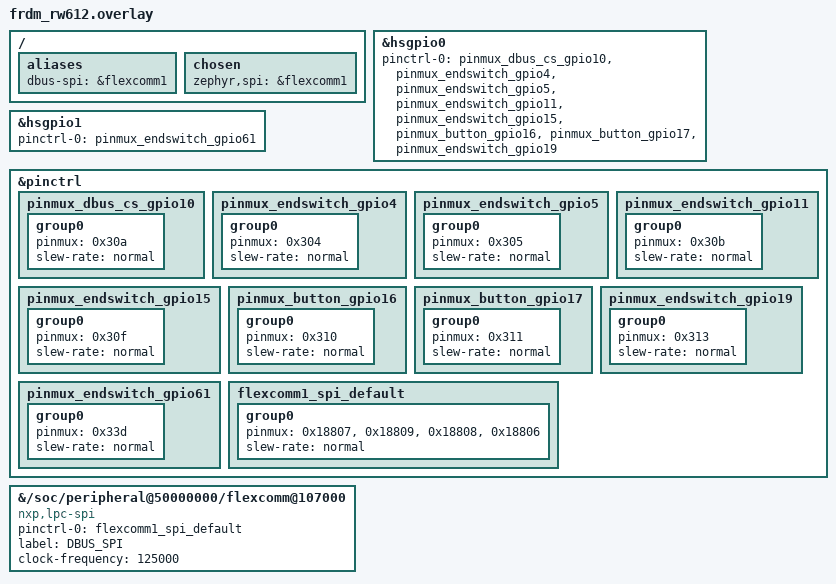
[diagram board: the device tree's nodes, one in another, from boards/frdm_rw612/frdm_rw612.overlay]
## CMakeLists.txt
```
cmake_minimum_required(VERSION 3.20.0)

if(NOT DEFINED DTC_OVERLAY_FILE OR DTC_OVERLAY_FILE STREQUAL "")
	set(_dbus_overlay "${CMAKE_CURRENT_SOURCE_DIR}/boards/frdm_rw612/frdm_rw612.overlay")
	if(EXISTS "${_dbus_overlay}")
		set(DTC_OVERLAY_FILE "${_dbus_overlay}" CACHE STRING "Default devicetree overlay" FORCE)
	endif()
endif()

find_package(Zephyr REQUIRED HINTS $ENV{ZEPHYR_BASE})
project(zephyr_dbus_driver)

# Add your source files here
target_sources(app PRIVATE src/main.c src/dbus_app_layer.c src/spi_abstraction.c src/dbus_config.c src/dbus_driver.c src/StdCrc.c src/motor_service.c src/lcd_service.c src/ultrasonic_service.c)
target_include_directories(app PRIVATE inc src)
target_compile_definitions(app PRIVATE ARCH_STACK_PTR_ALIGN=8) # Define for main application build
```

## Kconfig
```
config PRINTK_WAITTIME_MS
    int "Waittime in ms"
    default 100
    help
      Defines the waittime in ms after which
      "Hello World!" is printed to the console

source "Kconfig.zephyr"

config DBAL_CROSS_CONNECTION
	bool "Enable DBAL Cross Connection"
	default n
	help
		Enable this option to allow cross-connection functionality in the DBus Application Layer.

config DBAL_TARGET_ADDRESS
	hex "DBAL Target Address"
	default 0x00
	help
		Defines the target address for the DBus Application Layer.
		This address is used to identify the communication partner.

config DBAL_TX_THREAD_STACK_SIZE
	int "DBAL Transmit Thread Stack Size"
	default 4096
	help
		Stack size for the DBus Application Layer Transmit thread.

config DBAL_RX_THREAD_STACK_SIZE
	int "DBAL Receive Thread Stack Size"
	default 4096
	help
		Stack size for the DBus Application Layer Receive thread.
```

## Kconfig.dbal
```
menu "DBus Application Layer Configuration"

config DBAL_CROSS_CONNECTION
    bool "Enable DBAL Cross Connection"
    default y
    help
        Enable support for DBAL cross-connection features.

config DBAL_TX_THREAD_STACK_SIZE
    int "DBAL Transmit Thread Stack Size"
    default 4096
    depends on DBAL_CROSS_CONNECTION
    help
        Stack size for the DBus Application Layer Transmit Thread.

config DBAL_RX_THREAD_STACK_SIZE
    int "DBAL Receive Thread Stack Size"
    default 4096
    depends on DBAL_CROSS_CONNECTION
    help
        Stack size for the DBus Application Layer Receive Thread.

config DBAL_TARGET_ADDRESS
    hex "DBAL Target Address"
    default 0x01
    help
        The target address for DBAL communication.

endmenu
```

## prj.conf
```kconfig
# ==============================
# 🔧 Zephyr Kernel Configuration
# ==============================
CONFIG_MAIN_STACK_SIZE=4096
CONFIG_ISR_STACK_SIZE=2048
CONFIG_SYSTEM_WORKQUEUE_STACK_SIZE=2048
CONFIG_LOG_PROCESS_THREAD_STACK_SIZE=2048
CONFIG_HEAP_MEM_POOL_SIZE=1024
CONFIG_SYS_CLOCK_EXISTS=y
CONFIG_SYS_CLOCK_TICKS_PER_SEC=1000

# Thread diagnostics and safety
CONFIG_THREAD_NAME=y
CONFIG_THREAD_STACK_INFO=y
CONFIG_STACK_SENTINEL=y
CONFIG_STACK_CANARIES=y
CONFIG_THREAD_ANALYZER=y
CONFIG_THREAD_ANALYZER_AUTO=n
CONFIG_THREAD_ANALYZER_RUN_UNLOCKED=y
CONFIG_THREAD_ANALYZER_USE_PRINTK=y

# ==============================
# 🧾 Logging / Console
# ==============================
CONFIG_PRINTK=y
CONFIG_CONSOLE=y
CONFIG_SERIAL=y
CONFIG_UART_CONSOLE=y
CONFIG_LOG=y
CONFIG_LOG_DEFAULT_LEVEL=3
CONFIG_LOG_MODE_DEFERRED=y
CONFIG_LOG_PROCESS_THREAD=y
CONFIG_LOG_PROCESS_THREAD_STACK_SIZE=2048
CONFIG_LOG_BACKEND_UART=y
CONFIG_LOG_BUFFER_SIZE=2048

# RTT console for debugging (optional but great for NXP boards)
CONFIG_USE_SEGGER_RTT=y
CONFIG_LOG_BACKEND_RTT=y
CONFIG_SEGGER_RTT_BUFFER_SIZE_UP=4096
CONFIG_SEGGER_RTT_PRINTF_BUFFER_SIZE=512
CONFIG_RTT_CONSOLE=y

# ==============================
# ⚙️ Drivers
# ==============================
CONFIG_GPIO=y
CONFIG_SPI=y
CONFIG_SPI_ASYNC=y
CONFIG_SPI_INIT_PRIORITY=70
CONFIG_SPI_MCUX_FLEXCOMM=y

# ==============================
# 💾 Floating-Point Unit (optional)
# ==============================
# Only enable if your app really needs FPU math
# Otherwise it bloats context switching and stack usage
# Disable if not using floats in your code
CONFIG_FPU=y
CONFIG_FPU_SHARING=y

# ==============================
# 🧩 Custom DBAL (DBus Application Layer)
# ==============================
CONFIG_DBAL_CROSS_CONNECTION=y
CONFIG_DBAL_TARGET_ADDRESS=0x00
CONFIG_DBAL_TX_THREAD_STACK_SIZE=4096
CONFIG_DBAL_RX_THREAD_STACK_SIZE=4096

# ==============================
# 🧪 Testing (optional)
# ==============================
# CONFIG_ZTEST=y

# ==============================
# 🧠 Misc sanity
# ==============================
CONFIG_STACK_ALIGN_DOUBLE_WORD=y
CONFIG_KERNEL_INIT_PRIORITY_DEFAULT=90
```

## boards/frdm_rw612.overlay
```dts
/* frdm_rw612.overlay
 * SPI-Master setup for FRDM-RW612 using Flexcomm1
 */

#include <nxp/rw/RW612-pinctrl.h>

/ {
    aliases {
        dbus-spi = &flexcomm1;  /* alias for convenience */
    };

    chosen {
        zephyr,spi = &flexcomm1;
    };
};

&hsgpio0 {
    status = "okay";
};

/* Define pin configuration for SPI (manual CS via GPIO6). */
&pinctrl {
    flexcomm1_spi_default: flexcomm1_spi_default {
        group0 {
            pinmux = <0x18807>,  /* SCK  -> GPIO7 */
                     <0x18809>,  /* MOSI -> GPIO9 */
                     <0x18808>;  /* MISO -> GPIO8 */
            slew-rate = "normal";
        };
    };
};

/* Override SPI controller node. */
&flexcomm1 {
    status = "okay";
    compatible = "nxp,lpc-spi";
    pinctrl-0 = <&flexcomm1_spi_default>;
    pinctrl-names = "default";
    clock-frequency = <125000>;
};
```

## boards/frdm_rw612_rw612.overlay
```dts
/* Qualifier-specific overlay for frdm_rw612/rw612 */

#include "frdm_rw612.overlay"
```

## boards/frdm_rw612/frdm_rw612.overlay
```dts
/* frdm_rw612.overlay
 * SPI-Master setup for FRDM-RW612 using Flexcomm1
 */

#include <nxp/rw/RW612-pinctrl.h>

/ {
    aliases {
        dbus-spi = &flexcomm1;  // alias for convenience
    };

    chosen {
        zephyr,spi = &flexcomm1;
    };
};

&hsgpio0 {
    status = "okay";
    pinctrl-0 = <&pinmux_dbus_cs_gpio10
                 &pinmux_endswitch_gpio4
                 &pinmux_endswitch_gpio5
                 &pinmux_endswitch_gpio11
                 &pinmux_endswitch_gpio15
                 &pinmux_button_gpio16
                 &pinmux_button_gpio17
                 &pinmux_endswitch_gpio19>;
    pinctrl-names = "default";
};

&hsgpio1 {
    status = "okay";
    pinctrl-0 = <&pinmux_endswitch_gpio61>;
    pinctrl-names = "default";
};

/* --- Define pin configuration for SPI --- */
&pinctrl {
    pinmux_dbus_cs_gpio10: pinmux_dbus_cs_gpio10 {
        group0 {
            pinmux = <0x30a>; /* GPIO10 as HSGPIO0_10 for secondary Pico CS */
            slew-rate = "normal";
        };
    };

    pinmux_endswitch_gpio4: pinmux_endswitch_gpio4 {
        group0 {
            pinmux = <0x304>; /* GPIO4 as HSGPIO0_4 for motor1 max/end */
            slew-rate = "normal";
        };
    };

    pinmux_endswitch_gpio5: pinmux_endswitch_gpio5 {
        group0 {
            pinmux = <0x305>; /* GPIO5 as HSGPIO0_5 for motor2 min/home */
            slew-rate = "normal";
        };
    };

    pinmux_endswitch_gpio11: pinmux_endswitch_gpio11 {
        group0 {
            pinmux = <0x30b>; /* GPIO11 as HSGPIO0_11 for motor2 max/end */
            slew-rate = "normal";
        };
    };

    pinmux_endswitch_gpio15: pinmux_endswitch_gpio15 {
        group0 {
            pinmux = <0x30f>; /* GPIO15 as HSGPIO0_15 for motor1 min/home */
            slew-rate = "normal";
        };
    };

    pinmux_button_gpio16: pinmux_button_gpio16 {
        group0 {
            pinmux = <0x310>; /* GPIO16 as HSGPIO0_16 for alternate trigger button */
            slew-rate = "normal";
        };
    };

    pinmux_button_gpio17: pinmux_button_gpio17 {
        group0 {
            pinmux = <0x311>; /* GPIO17 as HSGPIO0_17 for combined-test trigger button */
            slew-rate = "normal";
        };
    };

    pinmux_endswitch_gpio19: pinmux_endswitch_gpio19 {
        group0 {
            pinmux = <0x313>; /* GPIO19 as HSGPIO0_19 for motor0 end-switch max/end */
            slew-rate = "normal";
        };
    };

    pinmux_endswitch_gpio61: pinmux_endswitch_gpio61 {
        group0 {
            pinmux = <0x33d>; /* GPIO61 as HSGPIO1_29 for motor0 end-switch min/home */
            slew-rate = "normal";
        };
    };

    flexcomm1_spi_default: flexcomm1_spi_default {
        group0 {
            pinmux = <0x18807>,  /* SCK  -> GPIO7   */
                     <0x18809>,  /* MOSI -> GPIO9   */
                     <0x18808>,  /* MISO -> GPIO8   */
                     <0x18806>;  /* SSEL0 -> GPIO6  */
            slew-rate = "normal";
        };
    };
};

/* --- Forcefully override SPI controller node --- */
&{/soc/peripheral@50000000/flexcomm@107000} {
    status = "okay";
    compatible = "nxp,lpc-spi";
    pinctrl-0 = <&flexcomm1_spi_default>;
    pinctrl-names = "default";
    label = "DBUS_SPI";
    /* CS is handled manually via HSGPIO GPIO6/GPIO10 in dbus_driver.c. */
    clock-frequency = <125000>; /* Set to 125kHz as per working BSHG example */
};
```

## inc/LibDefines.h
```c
#ifndef LIB_DEFINES_H
#define LIB_DEFINES_H

// Placeholder for common library definitions
// Add any necessary definitions here to allow compilation

// Example of a macro that might be in LibDefines.h
#define LD_STRINGIZE_NX(x) #x
#define LD_STRINGIZE(x) LD_STRINGIZE_NX(x)

#endif // LIB_DEFINES_H
```

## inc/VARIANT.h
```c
#ifndef VARIANT_H
#define VARIANT_H

// Placeholder for variant-specific definitions
// Add any necessary definitions here to allow compilation
// For example, if a specific macro is expected:
// #define SOME_VARIANT_SPECIFIC_MACRO_VALUE 1

#endif // VARIANT_H
```

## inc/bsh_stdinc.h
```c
#ifndef BSH_STDINC_H
#define BSH_STDINC_H

#ifdef __cplusplus
extern "C" {
#endif

#include "LibDefines.h"
#include LD_STRINGIZE(VARIANT.h) // include the header for current variant

// Placeholder for other standard includes or definitions from original bsh_stdinc.h
// For example, if it defines common integer types:
// #include <stdint.h>
// #include <stdbool.h>

#ifdef __cplusplus
}
#endif

#endif // BSH_STDINC_H
```

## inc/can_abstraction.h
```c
#ifndef ZEPHYR_CAN_ABSTRACTION_H__
#define ZEPHYR_CAN_ABSTRACTION_H__

#include <zephyr/kernel.h>
#include <stdbool.h>
#include <stdint.h>

/**
 * @brief Initializes the CAN abstraction layer.
 *
 * This function initializes the underlying Zephyr CAN device.
 *
 * @return True if initialization is successful, false otherwise.
 */
bool can_abstraction_init(void);

/**
 * @brief Sends a CAN message.
 *
 * @param id The CAN message ID.
 * @param data Pointer to the data to send.
 * @param len Length of the data.
 *
 * @return True if the message is successfully queued for transmission, false otherwise.
 */
bool can_abstraction_send(uint32_t id, const uint8_t *data, uint8_t len);

/**
 * @brief Registers a callback for CAN message reception.
 *
 * @param callback The function to call when a CAN message is received.
 */
void can_abstraction_register_rx_callback(void (*callback)(uint32_t id, const uint8_t *data, uint8_t len));

#endif // ZEPHYR_CAN_ABSTRACTION_H__
```

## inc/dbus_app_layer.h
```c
#ifndef ZEPHYR_DBUS_APP_LAYER_H__
#define ZEPHYR_DBUS_APP_LAYER_H__

#include <zephyr/kernel.h>
#include <stdbool.h>
#include <stdint.h>

// Define a structure for SPI received messages to be put into a message queue
#define DBAL_SPI_RX_MSG_MAX_SIZE    128 // Max size of an SPI message payload
#define DBAL_SPI_RX_MSG_QUEUE_DEPTH 10  // Depth of the message queue

struct dbal_spi_rx_msg {
    uint8_t data[DBAL_SPI_RX_MSG_MAX_SIZE];
    uint8_t len;
};

// Define uchar for compatibility with original code
typedef unsigned char uchar;

// Forward declaration for internal instance structure, if needed
// Define some constants from the original DBAL for Zephyr porting
#define DBAL_MAX_MSGS2REPEAT        10U // Example value, adjust as needed
#define DBAL_DBUS_RETRY_MAX         3U  // Example value, adjust as needed
#define DBAL_RESPONSE_TIME_MS       100 // Example value, adjust as needed
#define DBAL_DBUS_RECOVERY_TIME_MS  500 // Example value, adjust as needed

// Define message index constants (from original bustypes.h or similar)
#define DBAL_MSG_INDEX_APP_LAYER_CONNECTION 0U
#define DBAL_MSG_INDEX_APP_LAYER_REQUEST    1U
#define DBAL_MSG_INDEX_APP_LAYER_RESPONSE   2U
#define DBAL_MSG_INDEX_CROSS_OFFSET         3U // Offset for cross-connection messages
#define DBAL_MSG_INDEX_APP_LAYER_CROSS_CON  (DBAL_MSG_INDEX_APP_LAYER_CONNECTION + DBAL_MSG_INDEX_CROSS_OFFSET)
#define DBAL_MSG_INDEX_APP_LAYER_CROSS_REQ  (DBAL_MSG_INDEX_APP_LAYER_REQUEST + DBAL_MSG_INDEX_CROSS_OFFSET)
#define DBAL_MSG_INDEX_APP_LAYER_CROSS_RESP (DBAL_MSG_INDEX_APP_LAYER_RESPONSE + DBAL_MSG_INDEX_CROSS_OFFSET)
#define DBAL_MSG_INDEX_COUNT                6U // Total number of message indices

// Define offsets within the DBus frame (from original BshDBus2AppLayer.c comments)
#define DBAL_MSG_SENDER                     0U
#define DBAL_MSG_PROTOCOL_TYPE              1U
#define DBAL_MSG_SEQID                      2U
#define DBAL_CON_MSG_TYPE                   2U
#define DBAL_CON_MSG_PROTOCOL_VERSION       3U
#define DBAL_CON_MSG_LEN                    4U // Length of connection message

#define DBAL_FRAME_PAYLOADLEN               1U
#define DBAL_FRAME_SERVICE_ID_HI            2U
#define DBAL_FRAME_SERVICE_ID_LO            3U
#define DBAL_FRAME_COMMAND_ID_HI            4U
#define DBAL_FRAME_COMMAND_ID_LO            5U
#define DBAL_FRAME_DATA_OFFSET              6U // Offset to actual data in a DBAL frame

#define BYTE_SIZE                           8U // For bit shifting

// Placeholder for DBAL_LAST_MSG2REPEAT (from original BshDBus2AppLayer.c)
#define DBAL_LAST_MSG2REPEAT                (DBAL_MAX_MSGS2REPEAT - 1U)

// Placeholder for DBAL_BUFFER_SIZE (from original BshDBus2AppLayer.c)
#define DBAL_BUFFER_SIZE                    128U // Example buffer size, adjust as needed

// SPI Message Framing
#define SPI_SOF_BYTE                        0xAA // Start of Frame byte
#define SPI_LENGTH_OFFSET                   1U   // Offset for length byte after SOF
#define SPI_CRC_OFFSET                      2U   // Offset for CRC byte after SOF and Length
#define SPI_HEADER_LEN                      3U   // SOF + Length + CRC byte

// CRC-8 definitions (example, adjust polynomial and initial value as needed)
#define CRC8_POLYNOMIAL                     0x07 // CRC-8-SAE J1850 polynomial
#define CRC8_INITIAL_VALUE                  0xFF

// Placeholder for DLL_ACK_STATUS values (from original dbusdll.h or similar)
#define DLL_ACK_NOT_RECEIVED                0U
#define DLL_ACK_OK                          1U
// Add other DLL_ACK_STATUS values as needed (e.g., DLL_ACK_BUSY, DLL_ACK_WRONG, DLL_ACK_TRANSMISSION_ABORTED)

// Placeholder for DBAL_ConnectionSmEvent (from original BshDBus2AppLayer_internal.h or similar)
enum DBAL_ConnectionSmEvent {
    DBAL_CON_SM_EVENT_ENABLE_REQUEST,
    DBAL_CON_SM_EVENT_ACCEPT,
    DBAL_CON_SM_EVENT_DISABLE_REQUEST,
    DBAL_CON_SM_EVENT_DISABLE_RESPONSE, // Added
    DBAL_CON_SM_EVENT_DISABLE_SILENT,
    DBAL_CON_SM_EVENT_REJECT,
    DBAL_CON_SM_EVENT_TEMP_ENABLE_REQUEST,
    DBAL_CON_SM_EVENT_TEMP_DISABLE_REQUEST
};

// Placeholder for DBAL_Dbus2FrameType (from original BshDBus2AppLayer_internal.h or similar)
enum DBAL_Dbus2FrameType {
    DBAL_DBUS2_FRAME_TYPE_REQ,
    DBAL_DBUS2_FRAME_TYPE_RESP,
    DBAL_DBUS2_FRAME_TYPE_CON,
    DBAL_DBUS2_FRAME_TYPE_UNKNOWN
};

// Placeholder for DBAL_Msgs2RepeatStatus (from original BshDBus2AppLayer_internal.h or similar)
enum DBAL_Msgs2RepeatStatus {
    DBAL_MSG2REPEAT_NONE,
    DBAL_MSG2REPEAT_EXIST
};

// Placeholder for DBAL_CODE_SEC_TASK and other code section masks
#define DBAL_CODE_SEC_TASK                  0x01U
#define DBAL_CODE_SEC_REQ_RESP_POST         0x02U
#define DBAL_CODE_SEC_CR_REQ_RESP_POST      0x04U
#define DBAL_CODE_SEC_REP_TIMER             0x08U

// Placeholder for DBAL_ConnectionState (from original IoConnectionHandling.h or similar)
enum DBAL_ConnectionState {
    DBAL_CONNECTIONSTATE_DISCONNECTED,
    DBAL_CONNECTIONSTATE_CONNECTING,
    DBAL_CONNECTIONSTATE_CONNECTED,
    DBAL_CONNECTIONSTATE_DISCONNECTING
};

// Placeholder for DBALCR_ParticipantType (from original BshDBus2AppLayerCross.h)
enum DBALCR_ParticipantType
{
    DBALCR_PART_TYPE_NONE,
    DBALCR_PART_TYPE_CLIENT,
    DBALCR_PART_TYPE_SERVER
};

// Forward declaration for internal instance structure
struct dbal_instance;

// Prototype for timer callbacks (Zephyr k_timer_handler_t signature)
void dbal_con_msg_timer_cb(struct k_timer *timer_id);
void dbal_msg_timer_cb(struct k_timer *timer_id);

/** \enum   DBAL_CommState
 *
 * \brief   Value that represents the current communication status.
 *
 * \details For meaning of values see general DBal specification.
**/
enum DBAL_CommState
{
    DBAL_COMMSTATE_DISCONNECTED = 0, // Initial state
    DBAL_COMMSTATE_NOT_READY,        // Renamed from 0 to 1
    DBAL_COMMSTATE_CONNECTING,       // Added
    DBAL_COMMSTATE_CONNECTED,
    DBAL_COMMSTATE_DISCONNECTING     // Added
};

/** \enum   DBAL_MessageType
 *
 * \brief   Value that represents the DBal specific message type for communication.
 *
 * \details For meaning of values see general DBal specification.
**/
enum DBAL_MessageType
{
    DBAL_TYPE_CMD,
    DBAL_TYPE_CMD_ACK,
    DBAL_TYPE_QUERY,
    DBAL_TYPE_QUERY_ACK,
    DBAL_TYPE_EVENT,
    DBAL_TYPE_EVENT_ACK,
    DBAL_TYPE_UNKNOWN
};

/** \enum   DBAL_ConnectionMessageType
 *
 * \brief   Value that represents the action in the connection handling.
 *
 * \details For meaning of values see general DBal specification.
**/
enum DBAL_ConnectionMessageType
{
    DBAL_CON_ENABLE_REQUEST = 0,
    DBAL_CON_ENABLE_RESPONSE,
    DBAL_CON_DISABLE_REQUEST,
    DBAL_CON_DISABLE_RESPONSE,
    DBAL_CON_PING_REQUEST,
    DBAL_CON_PING_RESPONSE,
    DBAL_CON_TEMP_ENABLE_REQUEST,
    DBAL_CON_TEMP_ENABLE_RESPONSE,
    DBAL_CON_TEMP_DISABLE_REQUEST,
    DBAL_CON_TEMP_DISABLE_RESPONSE,
    DBAL_CON_MSG_TYPE_COUNT
};

typedef void (*DBAL_ioCommStateCb)(enum DBAL_CommState CommState);
typedef void (*DBAL_ioMsgLostCb)(uint16_t ServiceId, uint16_t CommandId, const uint8_t* const Bytes, uint8_t DataLen);

/** \struct DBAL_Identifier
 *
 * \brief   Structure for the identification of a DBal message with a given ServiceId.
 *
 * \details For meaning of parameters see general DBal specification.
**/
struct DBAL_Identifier
{
    uint16_t                        CommandId;
    enum DBAL_MessageType           Type;
};

typedef void (*DBAL_Service)(const uint8_t* const Data, uint8_t DataLen);

/** \struct DBAL_ReceiveObject
 *
 * \brief   Structure for handling an incoming dbal message.
**/
struct DBAL_ReceiveObject
{
    struct DBAL_Identifier      Identifier;
    DBAL_Service                Service;
};

#ifdef CONFIG_DBAL_CROSS_CONNECTION
/** \struct DBALCR_ObjectTableEntry
 *
 * \brief   Structure for handling an incoming dbal cross-connection message.
 **/
struct DBALCR_ObjectTableEntry
{
    const void*                 ReceiveObject;
    uint16_t                    ServiceId;
    uint8_t                     ReceiveObjectSize;
};
#endif // CONFIG_DBAL_CROSS_CONNECTION

// Structure to hold registered service handlers
#define DBAL_MAX_SERVICE_HANDLERS 5 // Example max number of service handlers
struct DBAL_ServiceHandler {
    uint16_t ServiceId;
    enum DBAL_MessageType Type;
    DBAL_Service Handler;
};

// Public function declarations
void dbal_init(void);
bool dbal_send_cmd_response(uint16_t service_id, uint16_t command_id, const uint8_t* data, uint8_t data_len);
bool dbal_send_query_response(uint16_t service_id, uint16_t command_id, const uint8_t* data, uint8_t data_len);
bool dbal_send_event(uint16_t service_id, uint16_t command_id, const uint8_t* data, uint8_t data_len);

/**
 * @brief Registers a DBus service handler.
 *
 * @param service_id The ID of the service to register.
 * @param type The message type (CMD, QUERY, EVENT) this handler is for.
 * @param handler The callback function to be executed when a matching message is received.
 *
 * @return True if registration is successful, false otherwise.
 */
bool dbal_register_service_handler(uint16_t service_id, enum DBAL_MessageType type, DBAL_Service handler);

/**
 * @brief Gets the current connection state of the DBAL instance.
 *
 * @return The current DBAL_CommState.
 */
enum DBAL_CommState dbal_get_connection_state(void);

// Public function declarations for DBus Lock functionality
bool dbal_apply_dbus_lock(void);
void dbal_release_dbus_lock(void);
bool dbal_is_dbus_lock_active(void);

/**
 * @brief Sends an ACK or NACK message in response to a received message.
 *
 * @param service_id The service ID of the received message.
 * @param command_id The command ID of the received message.
 * @param success True if the received message was processed successfully, false for NACK.
 * @return True if the ACK/NACK message was successfully sent, false otherwise.
 */
bool dbal_send_ack_nack(uint16_t service_id, uint16_t command_id, bool success);

// Test-only functions for service handler management
uint8_t dbal_get_num_service_handlers(void);
void dbal_reset_service_handlers_for_test(void);

#endif // ZEPHYR_DBUS_APP_LAYER_H__
```

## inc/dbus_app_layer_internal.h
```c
#ifndef ZEPHYR_DBUS_APP_LAYER_INTERNAL_H__
#define ZEPHYR_DBUS_APP_LAYER_INTERNAL_H__

#include <zephyr/kernel.h>
#include <stdbool.h>
#include <stdint.h>
#include <zephyr/sys/atomic.h>
#include "dbus_app_layer.h" // Include main header for DBAL_MessageType, DBAL_CommState, DBAL_MAX_MSGS2REPEAT, DBAL_ioMsgLostCb

// Internal structure for a message to be repeated
struct dbal_msg_to_repeat {
    bool IsSlotOccupied;
    uint8_t MsgRetryCounter;
    enum DBAL_MessageType DbalType; // Assuming DBAL_MessageType is defined in dbus_app_layer.h
    uint16_t ServiceId;
    uint16_t CommandId;
    uint8_t Datalen;
    uint8_t Data[64]; // Example max data length, adjust as needed
};

// Internal structure for the DBAL instance
struct dbal_instance {
    uint8_t DBUS_ComPartner;
    uint8_t DBUS_ComBackup;
    uint8_t SendRetryCounter[3]; // Assuming 3 message types for now (connection, request, response)
    struct k_timer ConMsgTimer; // Zephyr timer for connection messages
    struct k_timer MsgTimer;    // Zephyr timer for general messages
    uint8_t ConnectTransmitBuffer[4]; // Example size for connection messages
    uint8_t ConnectDataLen;
    uint8_t TransmitBuffer[128]; // Example max transmit buffer size
    uint8_t TransmitDataLen;
    uint8_t DbalFrames2TransmitCnt;
    uint8_t SeqId2Send;
    uint8_t LastSeqIdReceived;
    bool DisableReqReceived;
    enum DBAL_CommState IoCurrentConnectionState; // Placeholder for connection state
    struct dbal_msg_to_repeat Msgs2Repeat[DBAL_MAX_MSGS2REPEAT]; // Assuming DBAL_MAX_MSGS2REPEAT is defined in dbus_app_layer.h
    struct dbal_msg_to_repeat* MsgRptPtrs[DBAL_MAX_MSGS2REPEAT]; // Pointers for managing the queue
    uint8_t ConRepeatCnt;
    uint8_t LastSendingStatus[3]; // Placeholder for DLL_ACK_STATUS
    DBAL_ioMsgLostCb IoMsgLostCbArray[1]; // Placeholder for message lost callback
    uint8_t IoMsgLostCbCounter;
    uint8_t CodeSectionBitMask; // Placeholder for critical section flags
};

// Global instance for simplicity, or could be managed via a context pointer
extern struct dbal_instance g_dbal_main_instance;

#endif // ZEPHYR_DBUS_APP_LAYER_INTERNAL_H__
```

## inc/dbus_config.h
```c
#ifndef ZEPHYR_DBUS_CONFIG_H__
#define ZEPHYR_DBUS_CONFIG_H__

#include <stdint.h>
#include <stdbool.h>
#include "dbus_app_layer.h" // Include for DBAL_ReceiveObject and DBAL_Identifier

// Define constants from original DBal_cfg.c or derived from it
#define DBAL_OWN_NODE_ADDRESS       0x10U // Example: Own node address
#define DBAL_APPLIANCE_LAYER        0x01U // Example: Appliance layer protocol type
#define DBAL_PROTOCOL_VERSION       0x01U // Example: DBAL protocol version
#define DBAL_PRELIMINARY_PARTNER_ADDR 0x00U // Example: Preliminary partner address

// Placeholder for DBAL_ObjectTable and DBAL_ObjectTableSize
// These would typically be defined by the application using the DBAL
// For now, we'll provide a dummy structure.
struct DBAL_ObjectTableEntry {
    const struct DBAL_ReceiveObject *ReceiveObject;
    const uint16_t                  ServiceId;
    const uint8_t                   ReceiveObjectCount;
};

// Example dummy table and size
extern const struct DBAL_ObjectTableEntry DBAL_ObjectTable[];
extern const uint8_t DBAL_ObjectTableSize;

// Placeholder for cross-connection configurations if CONFIG_DBAL_CROSS_CONNECTION is enabled
#ifdef CONFIG_DBAL_CROSS_CONNECTION
#define DBAL_CROSS_CONNECT_COUNT    1U // Example: Number of cross connections
extern uint8_t DBALCR_ComPartners[DBAL_CROSS_CONNECT_COUNT];
extern enum DBALCR_ParticipantType DBALCR_RolesTowardPartners[DBAL_CROSS_CONNECT_COUNT];
extern uint16_t DBALCR_PingTimeMs;
#endif // CONFIG_DBAL_CROSS_CONNECTION

#endif // ZEPHYR_DBUS_CONFIG_H__
```

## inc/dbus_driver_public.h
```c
#ifndef DBUS_DRIVER_PUBLIC_H__
#define DBUS_DRIVER_PUBLIC_H__

#include "dbus_driver_config.h" // For MCAL_Error, DBC_Error, DBC_Cfg_t, etc.
#include <stdint.h>
#include <stdbool.h>
#include <zephyr/drivers/gpio.h> // Required for struct gpio_callback

enum MEXTI_Trigger {
    MEXTI_TRIGGER_FALLING = 0, // Placeholder
    MEXTI_TRIGGER_RISING, // Added dummy member
};

struct MEXTI_Config {
    enum MEXTI_Trigger trigger; // Placeholder
};

// Forward declaration for gpio_callback
struct gpio_callback;

// MEXTI_Handle definition
struct MEXTI_Handle {
    struct gpio_callback gpio_cb;
    MCAL_Callback_t *mcal_cb;
    uint32_t channel; // Store the channel for context in the callback
};

struct MSPI_Channel {
    void *mspi;
    const struct MDIO_Channel *sclk;
    const struct MDIO_Channel *miso;
    const struct MDIO_Channel *mosi;
    const struct MDIO_Channel *cs;
};

enum DBCDRV_SpiTarget {
    DBCDRV_SPI_TARGET_PRIMARY_PICO = 0,
    DBCDRV_SPI_TARGET_SECONDARY_PICO,
    DBCDRV_SPI_TARGET_COUNT,
};

// MCAL function prototypes
enum MCAL_Error MDIO_init(const struct MDIO_Channel *channel, const void *config);
const struct MDIO_Channel *MEXTI_getPin(uint32_t channel);
bool MDIO_read(const struct MDIO_Channel *channel);
void MDIO_toggle(const struct MDIO_Channel *channel);
void MDIO_write(const struct MDIO_Channel *channel, bool value);
enum MCAL_Error MEXTI_init(struct MEXTI_Handle *handle, uint32_t channel, const struct MEXTI_Config *config);
void MCAL_initCallback(MCAL_Callback_t *cb, MCAL_CallbackFunction_t func, void *obj);
enum MCAL_Error MEXTI_enableEvent(struct MEXTI_Handle *handle, MCAL_Callback_t *cb);
void MEXTI_disableEvent(struct MEXTI_Handle *handle, MCAL_Callback_t *cb);
enum MCAL_Error MSPI_init(struct MSPI_Handle *handle, const void *channel, const void *config);
uint32_t MSPI_getStatus(struct MSPI_Handle *handle);
enum MCAL_Error MSPI_transferDma(struct MSPI_Handle *handle, const uint8_t *writeBuf, uint16_t writeLen, uint8_t *readBuf, uint16_t readLen);
enum MCAL_Error MSPI_transfer(struct MSPI_Handle *handle, const uint8_t *writeBuf, uint16_t writeLen, uint8_t *readBuf, uint16_t readLen);
void MSPI_endCommunication(struct MSPI_Handle *handle);
enum MCAL_Error MDMA_disableChannelEvent(void *handle, MCAL_Callback_t *cb);
void MDMA_disableChannel(void *handle);
void MSPI_disableDMA(void *mspi);
enum MCAL_Error MSPI_transferBlocking(struct MSPI_Handle *handle, const uint8_t *writeBuf, uint16_t writeLen, uint8_t *readBuf, uint16_t readLen);
enum MCAL_Error MDMA_init(struct MDMA_Handle *handle, const void *periph, const void *channel);
void MSPI_initDma(struct MSPI_Handle *handle, struct MDMA_Handle *txHandle, struct MDMA_Handle *rxHandle);
enum MCAL_Error MSPI_enableEvent(struct MSPI_Handle *handle, MCAL_Callback_t *cb, uint32_t event);
void MSUP_setTimeOutExt(struct MSUP_TimeoutHandle *handle, uint32_t timeout_us);
bool MSUP_isTimeOutExt(struct MSUP_TimeoutHandle *handle);
void MSUP_delay(uint32_t delay_us);
uint32_t MTDIV_div_mod(uint32_t numerator, uint32_t denominator);
uint32_t MTDIV_div_32_32(uint32_t numerator, uint32_t denominator);

// DBCDRV function prototypes
DBC_Cfg_t DBCDRV_getConfig(void);
void DBCDRV_setSpiFrameHdr(enum DBC_RegAddr addr, uint16_t len, enum DBC_command cmd, uint8_t *writeBuf);
enum DBC_Error DBCDRV_readReg32(enum DBC_RegAddr addr, uint32_t *data);
enum DBC_Error DBCDRV_writeReg32(enum DBC_RegAddr addr, uint32_t data);
void DBCDRV_setSpiMode(bool cpol, bool cpha);
uint16_t DBCDRV_getSpiMode(void);
enum DBC_Error DBCDRV_setSpiTarget(enum DBCDRV_SpiTarget target);
enum DBCDRV_SpiTarget DBCDRV_getSpiTarget(void);
void DBCDRV_logSpiRouting(const char *tag);
enum DBC_Error DBCDRV_pulseCs(enum DBCDRV_SpiTarget target,
                              uint32_t pulse_count,
                              uint32_t low_time_us,
                              uint32_t high_time_us);
enum DBC_Error DBCDRV_writeRegIpec(uint32_t bitVal, uint32_t bitPos, uint32_t bitMask);
enum DBC_Error DBCDRV_writeEeprom(void);
bool DBCDRV_isSupplyForEepromWrite(void);
enum DBC_Error DBCDRV_setTableDbusBaudrate(uint32_t baudrate, uint32_t clockInput);
enum DBC_Error DBCDRV_setAnyDbusBaudrate(uint32_t baudrate, uint32_t clockInput);
uint32_t DBCDRV_getClockInputInHz(uint32_t clockInput);
enum DBC_Error DBCDRV_sendSpiFrame(enum DBC_command command, uint32_t address, uint8_t *txBuff, uint8_t *rxBuff, uint32_t len);
enum DBC_Error DBCDRV_sendSpiFrameNbl(enum DBC_command command, uint32_t address, uint8_t *txBuff, uint8_t *rxBuff, uint32_t len);
enum DBC_Error DBCDRV_setPowerModeStandby(void);
enum DBC_Error DBCDRV_doReset(bool *internalEepromError);
bool DBCDRV_isAllFeatureRevision(void);
enum DBC_Error DBCDRV_enableAndClearIrqFlags(uint32_t flags);
enum DBC_Error DBCDRV_configureRestForDbus(DBC_Cfg_t *config);
uint16_t DBCDRV_calculateCrc(uint8_t *data, uint32_t len);
enum DBC_Error DBCDRV_enableSpiCrc(void);
enum DBC_Error DBCDRV_disableSpiCrc(void);
enum MCAL_Error DBCDRV_dmaInit(void);
void DBCDRV_dmaCbFunction(void *obj, uint32_t flags, const void *eventResponse);
enum DBC_Error DBCDRV_initComChannels(MCAL_CallbackFunction_t irqHandleCbFunc);
enum DBC_Error DBCDRV_configure(DBC_Cfg_t cfg);
enum DBC_Error DBCDRV_init(void);

#endif // DBUS_DRIVER_PUBLIC_H__
```

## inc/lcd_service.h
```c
#ifndef LCD_SERVICE_H__
#define LCD_SERVICE_H__

#include <stdint.h>

#include "dbus_driver_public.h"

#define LCD_SERVICE_ID            0x7102u
#define LCD_CMD_CLEAR             0x0001u
#define LCD_CMD_PRINT             0x0002u
#define LCD_CMD_SET_CURSOR        0x0003u
#define LCD_TEXT_MAX_LEN          13u

enum DBC_Error lcd_service_clear(uint8_t display_index);
enum DBC_Error lcd_service_set_cursor(uint8_t display_index, uint8_t row, uint8_t col);
enum DBC_Error lcd_service_print(uint8_t display_index, uint8_t row, uint8_t col, const char *text);

#endif
```

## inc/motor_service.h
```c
#ifndef MOTOR_SERVICE_H__
#define MOTOR_SERVICE_H__

#include <stdbool.h>
#include <stdint.h>

#include "dbus_driver_public.h"

#define MOTOR_SERVICE_ID                  0x7100u
#define MOTOR_CMD_SET_ENABLE              0x0001u
#define MOTOR_CMD_SET_SPEED               0x0002u
#define MOTOR_CMD_GET_FEEDBACK            0x0003u
#define MOTOR_CMD_GET_STATUS              0x0004u

#define MOTOR_SERVICE_MAX_INDEX           3u
#define MOTOR_SERVICE_SPEED_ABS_MAX       1200

struct motor_enable_payload {
    uint8_t motor_index;
    uint8_t enable;
};

struct motor_speed_payload {
    uint8_t motor_index;
    int32_t speed_setpoint;
};

struct motor_index_payload {
    uint8_t motor_index;
};

struct motor_feedback_payload {
    uint8_t motor_index;
    int32_t speed_feedback;
};

struct motor_status_payload {
    uint8_t motor_index;
    uint32_t status;
};

bool motor_service_encode_enable_payload(uint8_t motor_index, bool enable, struct motor_enable_payload *payload);
bool motor_service_encode_speed_payload(uint8_t motor_index, int32_t speed_setpoint, struct motor_speed_payload *payload);
bool motor_service_encode_index_payload(uint8_t motor_index, struct motor_index_payload *payload);

enum DBC_Error motor_service_set_enable(uint8_t motor_index, bool enable);
enum DBC_Error motor_service_set_speed(uint8_t motor_index, int32_t speed_setpoint);
enum DBC_Error motor_service_get_feedback(uint8_t motor_index, int32_t *speed_feedback);
enum DBC_Error motor_service_get_status(uint8_t motor_index, uint32_t *status);

#endif
```

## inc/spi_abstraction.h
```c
#ifndef ZEPHYR_DBUS_DRIVER_INC_SPI_ABSTRACTION_H_
#define ZEPHYR_DBUS_DRIVER_INC_SPI_ABSTRACTION_H_

#include <zephyr/types.h>
#include <stddef.h>
#include <zephyr/kernel.h> // Required for struct k_msgq

#ifdef __cplusplus
extern "C" {
#endif

/**
 * @brief Initializes the SPI abstraction layer.
 *
 * This function initializes the underlying SPI device.
 *
 * @return 0 on success, or a negative errno code on failure.
 */
int spi_abstraction_init(void);

/**
 * @brief Sends and receives data over SPI.
 *
 * This function performs a full-duplex SPI transfer.
 *
 * @param tx_data Pointer to the transmit buffer.
 * @param tx_len Length of the transmit buffer in bytes.
 * @param rx_data Pointer to the receive buffer.
 * @param rx_len Length of the receive buffer in bytes.
 *
 * @return 0 on success, or a negative errno code on failure.
 */
int spi_abstraction_send(const uint8_t *tx_data, size_t tx_len, uint8_t *rx_data, size_t rx_len);

// Forward declaration for the message queue structure
struct dbal_spi_rx_msg;

/**
 * @brief Type definition for the SPI RX callback function.
 *
 * @param data Pointer to the received data buffer.
 * @param len Length of the received data in bytes.
 */
typedef void (*spi_rx_callback_t)(const uint8_t *data, uint8_t len);

/**
 * @brief Registers a callback function for SPI received data.
 *
 * @param callback The function to be called when SPI data is received.
 */
void spi_abstraction_register_rx_callback(spi_rx_callback_t callback);

/**
 * @brief Sets the message queue for SPI received data.
 *
 * @param msg_q Pointer to the K_MSGQ object where received data will be put.
 */
void spi_abstraction_set_rx_msg_queue(struct k_msgq *msg_q);

#ifdef __cplusplus
}
#endif

#endif /* ZEPHYR_DBUS_DRIVER_INC_SPI_ABSTRACTION_H_ */
```
